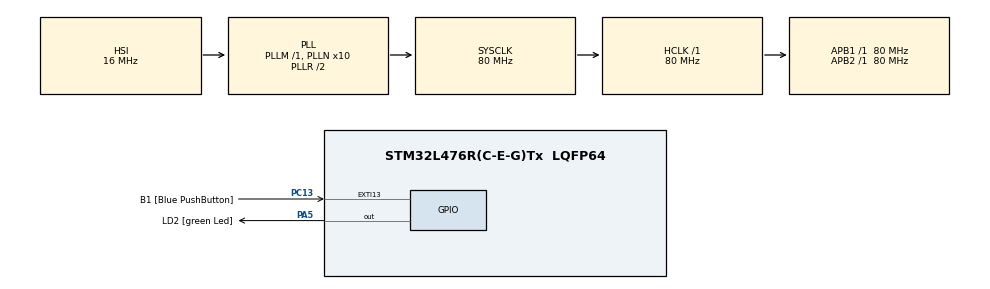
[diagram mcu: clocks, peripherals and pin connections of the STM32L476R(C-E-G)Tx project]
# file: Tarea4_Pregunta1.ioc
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Mcu.Family=STM32L4
Mcu.Name=STM32L476R(C-E-G)Tx
Mcu.Package=LQFP64
NVIC.EXTI15_10_IRQn=true\:0\:0\:false\:false\:true\:true\:true\:true
NVIC.PriorityGroup=NVIC_PRIORITYGROUP_4
PA0.Mode=SYS_WakeUp0
PA0.Signal=SYS_WKUP1
PA13\ (JTMS-SWDIO).GPIO_Label=TMS
PA13\ (JTMS-SWDIO).Mode=Serial_Wire
PA13\ (JTMS-SWDIO).Signal=SYS_JTMS-SWDIO
PA14\ (JTCK-SWCLK).GPIO_Label=TCK
PA14\ (JTCK-SWCLK).Mode=Serial_Wire
PA14\ (JTCK-SWCLK).Signal=SYS_JTCK-SWCLK
PA5.GPIO_Label=LD2 [green Led]
PA5.GPIO_ModeDefaultOutputPP=GPIO_MODE_OUTPUT_PP
PA5.GPIO_PuPd=GPIO_NOPULL
PA5.GPIO_Speed=GPIO_SPEED_FREQ_LOW
PA5.Signal=GPIO_Output
PB3\ (JTDO-TRACESWO).GPIO_Label=SWO
PB3\ (JTDO-TRACESWO).Signal=SYS_JTDO-SWO
PC13.GPIO_Label=B1 [Blue PushButton]
PC13.GPIO_ModeDefaultEXTI=GPIO_MODE_IT_FALLING
PC13.GPIO_PuPd=GPIO_NOPULL
PC13.Signal=GPXTI13
PC14-OSC32_IN\ (PC14).Mode=LSE-External-Oscillator
PC14-OSC32_IN\ (PC14).Signal=RCC_OSC32_IN
PC15-OSC32_OUT\ (PC15).Mode=LSE-External-Oscillator
PC15-OSC32_OUT\ (PC15).Signal=RCC_OSC32_OUT
PH0-OSC_IN\ (PH0).Signal=RCC_OSC_IN
PH1-OSC_OUT\ (PH1).Signal=RCC_OSC_OUT
ProjectManager.HeapSize=0x200
ProjectManager.StackSize=0x400
ProjectManager.TargetToolchain=STM32CubeIDE
RCC.ADCFreq_Value=64000000
RCC.AHBFreq_Value=80000000
RCC.APB1Freq_Value=80000000
RCC.APB1TimFreq_Value=80000000
RCC.APB2Freq_Value=80000000
RCC.APB2TimFreq_Value=80000000
RCC.CortexFreq_Value=80000000
RCC.HCLKFreq_Value=80000000
RCC.HSE_VALUE=8000000
RCC.HSI_VALUE=16000000
RCC.MSI_VALUE=4000000
RCC.PLLN=10
RCC.PLLSourceVirtual=RCC_PLLSOURCE_HSI
RCC.PREFETCH_ENABLE=1
RCC.SYSCLKFreq_VALUE=80000000
RCC.SYSCLKSource=RCC_SYSCLKSOURCE_PLLCLK
RCC.USBFreq_Value=64000000
RCC.VCOOutputFreq_Value=160000000
VP_RTC_VS_RTC_Activate.Mode=RTC_Enabled
VP_RTC_VS_RTC_Calendar.Mode=RTC_Calendar
board=NUCLEO-L476RG

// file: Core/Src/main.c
/* USER CODE BEGIN Header */
/**
  ******************************************************************************
  * @file           : main.c
  * @brief          : Main program body
  ******************************************************************************
  * @attention
  *
  * Copyright (c) 2026 STMicroelectronics.
  * All rights reserved.
  *
  * This software is licensed under terms that can be found in the LICENSE file
  * in the root directory of this software component.
  * If no LICENSE file comes with this software, it is provided AS-IS.
  *
  ******************************************************************************
  */
/* USER CODE END Header */
#include "main.h"

/* USER CODE BEGIN PD */

#define BLINK_DELAY_MS   200   /* Duración de cada parpadeo del LED        */
#define RUN_TIME_MS      3000  /* Tiempo visible en Run Mode antes de dormir */

/* USER CODE END PD */

RTC_HandleTypeDef hrtc;

/* USER CODE BEGIN PV */

/*
 * mode 0 -> Run
 * mode 1 -> Sleep
 * mode 2 -> Stop 0
 * mode 3 -> Stop 1
 * mode 4 -> Stop 2
 * mode 5 -> Standby
 * mode 6 -> Shutdown
 *
 */
uint8_t mode = 0;
uint8_t next_mode=0;
volatile uint8_t exit_run=0;
/* USER CODE END PV */

void SystemClock_Config(void);
static void MX_GPIO_Init(void);
static void MX_RTC_Init(void);

/* USER CODE BEGIN 0 */

static void BlinkLED(uint8_t times)
{
	HAL_GPIO_WritePin(LD2_GPIO_Port, LD2_Pin, GPIO_PIN_RESET);
    for (uint8_t i = 0; i < times; i++)
    {
        HAL_GPIO_WritePin(LD2_GPIO_Port, LD2_Pin, GPIO_PIN_SET);
        HAL_Delay(BLINK_DELAY_MS);
        HAL_GPIO_WritePin(LD2_GPIO_Port, LD2_Pin, GPIO_PIN_RESET);
        HAL_Delay(BLINK_DELAY_MS);
    }
}

void Save_Mode_To_Backup(uint8_t mode) {
    // Habilita el dominio de backup
    HAL_PWR_EnableBkUpAccess();
    // Escribe el valor de mode en el registro
    HAL_RTCEx_BKUPWrite(&hrtc, RTC_BKP_DR0, (uint32_t)mode);
}

uint8_t Read_Mode_From_Backup(void) {
    // Lee el registro de backup
    return (uint8_t)HAL_RTCEx_BKUPRead(&hrtc, RTC_BKP_DR0);
}

/* USER CODE END 0 */

int main(void)
{

  /* MCU Configuration--------------------------------------------------------*/

  /* Reset of all peripherals, Initializes the Flash interface and the Systick. */
  HAL_Init();

  /* Configure the system clock */
  SystemClock_Config();

  /* Initialize all configured peripherals */
  MX_GPIO_Init();
  MX_RTC_Init();
  /* USER CODE BEGIN 2 */

  /* USER CODE BEGIN 2 */

  // Resetear backup al inicio
  if (__HAL_PWR_GET_FLAG(PWR_FLAG_SB) == RESET)
  {
      mode = 0;
      Save_Mode_To_Backup(mode);
  }
  else
  {
      mode = Read_Mode_From_Backup(); // Lee el valor cuando hay reset (Standby/Shutdown)

      // Limpiamos la bandera de Standby para el próximo ciclo
      __HAL_PWR_CLEAR_FLAG(PWR_FLAG_SB);
  }

  // Validación de seguridad
  if (mode > 6) mode = 0;

  /* USER CODE END 2 */

  /* Infinite loop */
  /* USER CODE BEGIN WHILE */
  while (1)
  {
      // Mostrar modo actual
      if (mode != 0)
      {
          BlinkLED(mode);  // ajustado al nuevo mapping
      }

      // primero blink
      if (mode == 1)
      {
          BlinkLED(1);
      }

      HAL_Delay(1000);

      HAL_SuspendTick();

      next_mode = (mode + 1) % 7;
      Save_Mode_To_Backup(next_mode);	// Guarda el valor de mode en backup

      switch(mode)
      {
      	  // 0 -> RUN
      	  case 0:
              HAL_GPIO_WritePin(LD2_GPIO_Port, LD2_Pin, GPIO_PIN_SET); // LED siempre encendido
              if (exit_run){
            	  exit_run = 0;
                  next_mode = 1; // ir a SLEEP
              }
              else{
            	  next_mode = 0; // quedarse en RUN
              }
              break;
          // 1 -> SLEEP
          case 1:
              HAL_PWR_EnterSLEEPMode(PWR_MAINREGULATOR_ON, PWR_SLEEPENTRY_WFI);
              break;

          // 2 -> STOP0
          case 2:
              HAL_PWREx_EnterSTOP0Mode(PWR_STOPENTRY_WFI);
              SystemClock_Config();	// Al detenerse el CPU, se debe configurar de nuevo
              break;

          // 3 -> STOP1
          case 3:
              HAL_PWREx_EnterSTOP1Mode(PWR_STOPENTRY_WFI);
              SystemClock_Config();
              break;

          // 4 -> STOP2
          case 4:
              HAL_PWREx_EnterSTOP2Mode(PWR_STOPENTRY_WFI);
              SystemClock_Config();
              break;

          // 5  -> STANDBY
          case 5:
              __HAL_PWR_CLEAR_FLAG(PWR_FLAG_WU);
              HAL_PWR_EnableWakeUpPin(PWR_WAKEUP_PIN1); // PA0
              HAL_PWR_EnterSTANDBYMode();
              break;

          // 6 -> SHUTDOWN
          case 6:
        	  HAL_Delay(4000);  // Tiempo para evitar rebote
              __HAL_PWR_CLEAR_FLAG(PWR_FLAG_WU);
              HAL_PWR_EnableWakeUpPin(PWR_WAKEUP_PIN1); // PA0
              HAL_PWREx_EnterSHUTDOWNMode();
              break;
      }

      HAL_ResumeTick();

      // Cambiar modo después de despertar
      mode = next_mode;
    /* USER CODE END WHILE */

  }
}

void SystemClock_Config(void)
{
  RCC_OscInitTypeDef RCC_OscInitStruct = {0};
  RCC_ClkInitTypeDef RCC_ClkInitStruct = {0};

  /** Configure the main internal regulator output voltage
  */
  if (HAL_PWREx_ControlVoltageScaling(PWR_REGULATOR_VOLTAGE_SCALE1) != HAL_OK)
  {
    Error_Handler();
  }

  /** Initializes the RCC Oscillators according to the specified parameters
  * in the RCC_OscInitTypeDef structure.
  */
  RCC_OscInitStruct.OscillatorType = RCC_OSCILLATORTYPE_HSI|RCC_OSCILLATORTYPE_LSI;
  RCC_OscInitStruct.HSIState = RCC_HSI_ON;
  RCC_OscInitStruct.HSICalibrationValue = RCC_HSICALIBRATION_DEFAULT;
  RCC_OscInitStruct.LSIState = RCC_LSI_ON;
  RCC_OscInitStruct.PLL.PLLState = RCC_PLL_ON;
  RCC_OscInitStruct.PLL.PLLSource = RCC_PLLSOURCE_HSI;
  RCC_OscInitStruct.PLL.PLLM = 1;
  RCC_OscInitStruct.PLL.PLLN = 10;
  RCC_OscInitStruct.PLL.PLLP = RCC_PLLP_DIV7;
  RCC_OscInitStruct.PLL.PLLQ = RCC_PLLQ_DIV2;
  RCC_OscInitStruct.PLL.PLLR = RCC_PLLR_DIV2;
  if (HAL_RCC_OscConfig(&RCC_OscInitStruct) != HAL_OK)
  {
    Error_Handler();
  }

  /** Initializes the CPU, AHB and APB buses clocks
  */
  RCC_ClkInitStruct.ClockType = RCC_CLOCKTYPE_HCLK|RCC_CLOCKTYPE_SYSCLK
                              |RCC_CLOCKTYPE_PCLK1|RCC_CLOCKTYPE_PCLK2;
  RCC_ClkInitStruct.SYSCLKSource = RCC_SYSCLKSOURCE_PLLCLK;
  RCC_ClkInitStruct.AHBCLKDivider = RCC_SYSCLK_DIV1;
  RCC_ClkInitStruct.APB1CLKDivider = RCC_HCLK_DIV1;
  RCC_ClkInitStruct.APB2CLKDivider = RCC_HCLK_DIV1;

  if (HAL_RCC_ClockConfig(&RCC_ClkInitStruct, FLASH_LATENCY_4) != HAL_OK)
  {
    Error_Handler();
  }
}

static void MX_RTC_Init(void)
{

  RTC_TimeTypeDef sTime = {0};
  RTC_DateTypeDef sDate = {0};

  /** Initialize RTC Only
  */
  hrtc.Instance = RTC;
  hrtc.Init.HourFormat = RTC_HOURFORMAT_24;
  hrtc.Init.AsynchPrediv = 127;
  hrtc.Init.SynchPrediv = 255;
  hrtc.Init.OutPut = RTC_OUTPUT_DISABLE;
  hrtc.Init.OutPutRemap = RTC_OUTPUT_REMAP_NONE;
  hrtc.Init.OutPutPolarity = RTC_OUTPUT_POLARITY_HIGH;
  hrtc.Init.OutPutType = RTC_OUTPUT_TYPE_OPENDRAIN;
  if (HAL_RTC_Init(&hrtc) != HAL_OK)
  {
    Error_Handler();
  }

  /** Initialize RTC and set the Time and Date
  */
  sTime.Hours = 0x0;
  sTime.Minutes = 0x0;
  sTime.Seconds = 0x0;
  sTime.DayLightSaving = RTC_DAYLIGHTSAVING_NONE;
  sTime.StoreOperation = RTC_STOREOPERATION_RESET;
  if (HAL_RTC_SetTime(&hrtc, &sTime, RTC_FORMAT_BCD) != HAL_OK)
  {
    Error_Handler();
  }
  sDate.WeekDay = RTC_WEEKDAY_MONDAY;
  sDate.Month = RTC_MONTH_JANUARY;
  sDate.Date = 0x1;
  sDate.Year = 0x0;

  if (HAL_RTC_SetDate(&hrtc, &sDate, RTC_FORMAT_BCD) != HAL_OK)
  {
    Error_Handler();
  }

}

static void MX_GPIO_Init(void)
{
  GPIO_InitTypeDef GPIO_InitStruct = {0};

  /* GPIO Ports Clock Enable */
  __HAL_RCC_GPIOC_CLK_ENABLE();
  __HAL_RCC_GPIOH_CLK_ENABLE();
  __HAL_RCC_GPIOA_CLK_ENABLE();
  __HAL_RCC_GPIOB_CLK_ENABLE();

  /*Configure GPIO pin Output Level */
  HAL_GPIO_WritePin(LD2_GPIO_Port, LD2_Pin, GPIO_PIN_RESET);

  /*Configure GPIO pin : B1_Pin */
  GPIO_InitStruct.Pin = B1_Pin;
  GPIO_InitStruct.Mode = GPIO_MODE_IT_FALLING;
  GPIO_InitStruct.Pull = GPIO_NOPULL;
  HAL_GPIO_Init(B1_GPIO_Port, &GPIO_InitStruct);

  /*Configure GPIO pin : LD2_Pin */
  GPIO_InitStruct.Pin = LD2_Pin;
  GPIO_InitStruct.Mode = GPIO_MODE_OUTPUT_PP;
  GPIO_InitStruct.Pull = GPIO_NOPULL;
  GPIO_InitStruct.Speed = GPIO_SPEED_FREQ_LOW;
  HAL_GPIO_Init(LD2_GPIO_Port, &GPIO_InitStruct);

  /* EXTI interrupt init*/
  HAL_NVIC_SetPriority(EXTI15_10_IRQn, 0, 0);
  HAL_NVIC_EnableIRQ(EXTI15_10_IRQn);

}

/* USER CODE BEGIN 4 */

void HAL_GPIO_EXTI_Callback(uint16_t GPIO_Pin)
{
    if (GPIO_Pin == B1_Pin)
    {
        exit_run = 1;
    }
}

/* USER CODE END 4 */

void Error_Handler(void)
{
  __disable_irq();
  while (1)
  {
  }
}
